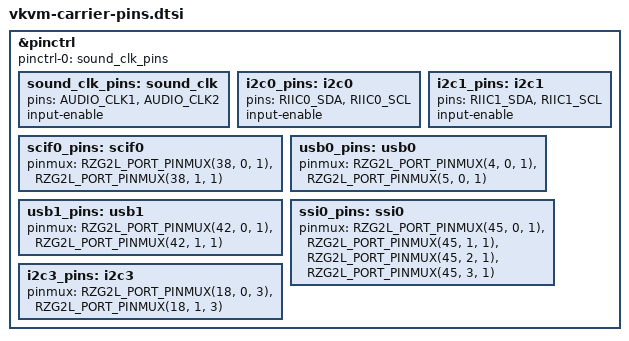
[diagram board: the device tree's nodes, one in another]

// SPDX-License-Identifier: (GPL-2.0-only OR BSD-2-Clause)
/*
 * Device Tree Source for the RZ/G2LC SMARC pincontrol parts
 *
 * Copyright (C) 2021 Renesas Electronics Corp.
 */

#include <dt-bindings/gpio/gpio.h>
#include <dt-bindings/pinctrl/rzg2l-pinctrl.h>


&pinctrl {
	pinctrl-0 = <&sound_clk_pins>;
	pinctrl-names = "default";

	sound_clk_pins: sound_clk {
		pins = "AUDIO_CLK1", "AUDIO_CLK2";
		input-enable;
	};

	i2c0_pins: i2c0 {
		pins = "RIIC0_SDA", "RIIC0_SCL";
		input-enable;
	};

	i2c1_pins: i2c1 {
		pins = "RIIC1_SDA", "RIIC1_SCL";
		input-enable;
	};

	scif0_pins: scif0 {
		pinmux = <RZG2L_PORT_PINMUX(38, 0, 1)>,	/* TxD */
			 <RZG2L_PORT_PINMUX(38, 1, 1)>;	/* RxD */
	};

	usb0_pins: usb0 {
		pinmux = <RZG2L_PORT_PINMUX(4, 0, 1)>, /* VBUS */
			 <RZG2L_PORT_PINMUX(5, 0, 1)>; /* OVC */
	};

	usb1_pins: usb1 {
		pinmux = <RZG2L_PORT_PINMUX(42, 0, 1)>, /* VBUS */
			 <RZG2L_PORT_PINMUX(42, 1, 1)>; /* OVC */
	};

	ssi0_pins: ssi0 {
		pinmux = <RZG2L_PORT_PINMUX(45, 0, 1)>, /* BCK */
			 <RZG2L_PORT_PINMUX(45, 1, 1)>, /* RCK */
			 <RZG2L_PORT_PINMUX(45, 2, 1)>, /* TXD */
			 <RZG2L_PORT_PINMUX(45, 3, 1)>; /* RXD */
	};

	i2c3_pins: i2c3 {
		pinmux = <RZG2L_PORT_PINMUX(18, 0, 3)>, /* SDA */
			 <RZG2L_PORT_PINMUX(18, 1, 3)>; /* SCL */
	};
};
